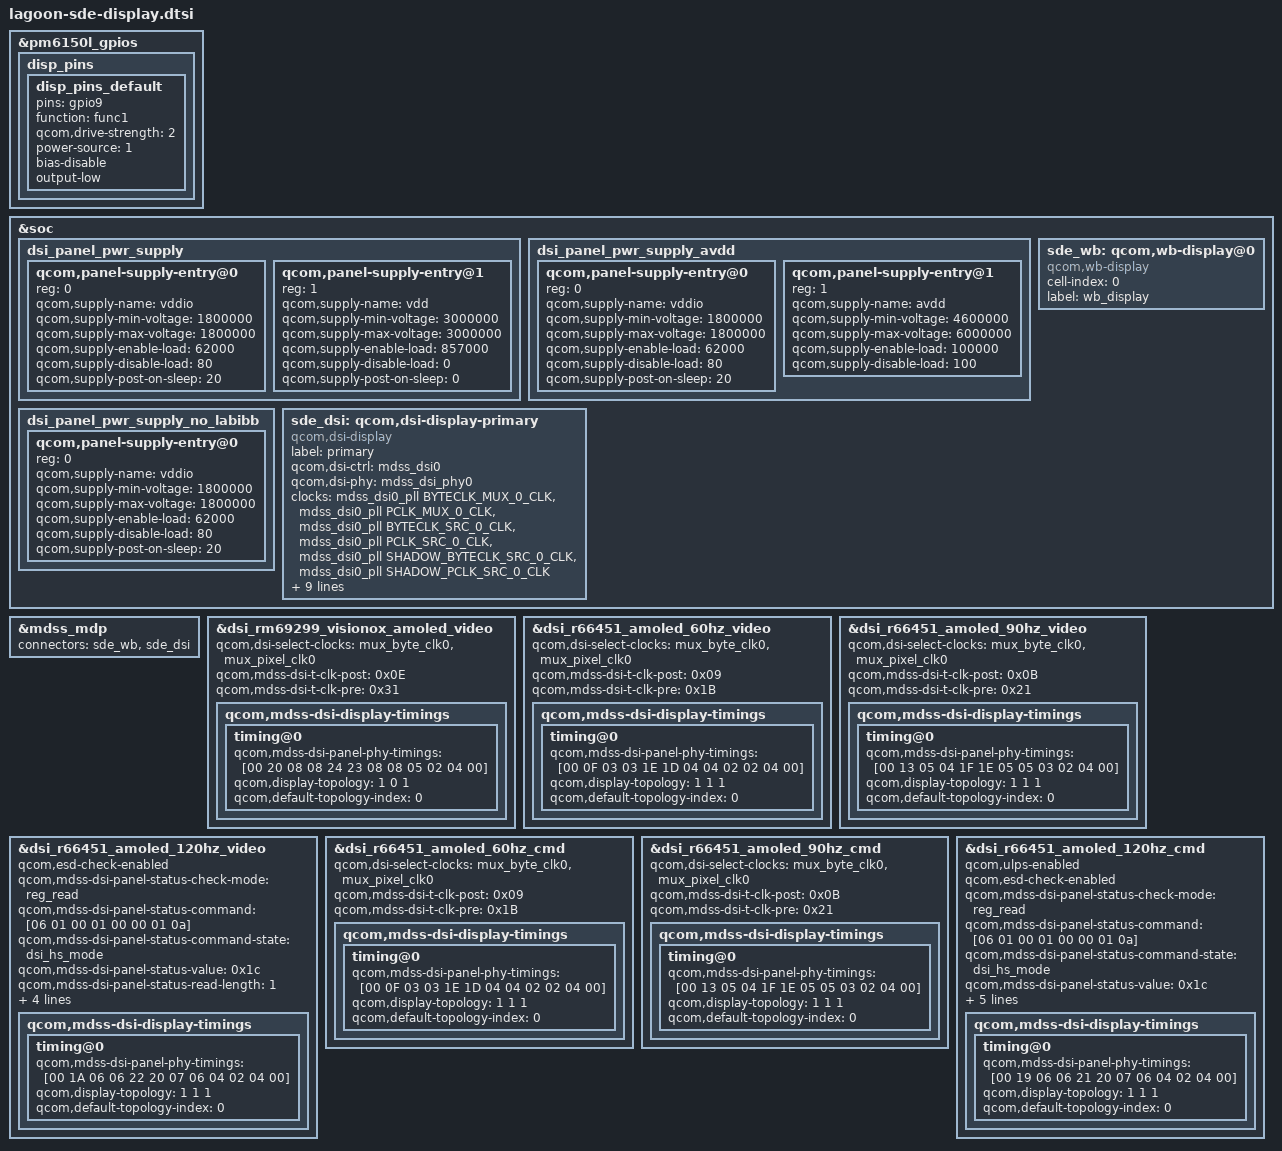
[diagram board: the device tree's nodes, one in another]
#include "dsi-panel-rm69299-visionox-fhd-plus-video.dtsi"
#include "dsi-panel-r66451-dsc-qhd-60hz-cmd.dtsi"
#include "dsi-panel-r66451-dsc-qhd-90hz-cmd.dtsi"
#include "dsi-panel-r66451-dsc-qhd-120hz-cmd.dtsi"
#include "dsi-panel-r66451-dsc-qhd-60hz-video.dtsi"
#include "dsi-panel-r66451-dsc-qhd-90hz-video.dtsi"
#include "dsi-panel-r66451-dsc-qhd-120hz-video.dtsi"

#include <dt-bindings/clock/mdss-10nm-pll-clk.h>

&pm6150l_gpios {
	disp_pins {
		disp_pins_default: disp_pins_default {
			pins = "gpio9";
			function = "func1";
			qcom,drive-strength = <2>;
			power-source = <1>;
			bias-disable;
			output-low;
		};
	};
};

&soc {
	dsi_panel_pwr_supply: dsi_panel_pwr_supply {
		#address-cells = <1>;
		#size-cells = <0>;

		qcom,panel-supply-entry@0 {
			reg = <0>;
			qcom,supply-name = "vddio";
			qcom,supply-min-voltage = <1800000>;
			qcom,supply-max-voltage = <1800000>;
			qcom,supply-enable-load = <62000>;
			qcom,supply-disable-load = <80>;
			qcom,supply-post-on-sleep = <20>;
		};

		qcom,panel-supply-entry@1 {
			reg = <1>;
			qcom,supply-name = "vdd";
			qcom,supply-min-voltage = <3000000>;
			qcom,supply-max-voltage = <3000000>;
			qcom,supply-enable-load = <857000>;
			qcom,supply-disable-load = <0>;
			qcom,supply-post-on-sleep = <0>;
		};
	};

	dsi_panel_pwr_supply_avdd: dsi_panel_pwr_supply_avdd {
		#address-cells = <1>;
		#size-cells = <0>;

		qcom,panel-supply-entry@0 {
			reg = <0>;
			qcom,supply-name = "vddio";
			qcom,supply-min-voltage = <1800000>;
			qcom,supply-max-voltage = <1800000>;
			qcom,supply-enable-load = <62000>;
			qcom,supply-disable-load = <80>;
			qcom,supply-post-on-sleep = <20>;
		};

		qcom,panel-supply-entry@1 {
			reg = <1>;
			qcom,supply-name = "avdd";
			qcom,supply-min-voltage = <4600000>;
			qcom,supply-max-voltage = <6000000>;
			qcom,supply-enable-load = <100000>;
			qcom,supply-disable-load = <100>;
		};
	};

	dsi_panel_pwr_supply_no_labibb: dsi_panel_pwr_supply_no_labibb {
		#address-cells = <1>;
		#size-cells = <0>;

		qcom,panel-supply-entry@0 {
			reg = <0>;
			qcom,supply-name = "vddio";
			qcom,supply-min-voltage = <1800000>;
			qcom,supply-max-voltage = <1800000>;
			qcom,supply-enable-load = <62000>;
			qcom,supply-disable-load = <80>;
			qcom,supply-post-on-sleep = <20>;
		};
	};

	sde_dsi: qcom,dsi-display-primary {
		compatible = "qcom,dsi-display";
		label = "primary";

		qcom,dsi-ctrl = <&mdss_dsi0>;
		qcom,dsi-phy = <&mdss_dsi_phy0>;

		clocks = <&mdss_dsi0_pll BYTECLK_MUX_0_CLK>,
			 <&mdss_dsi0_pll PCLK_MUX_0_CLK>,
			 <&mdss_dsi0_pll BYTECLK_SRC_0_CLK>,
			 <&mdss_dsi0_pll PCLK_SRC_0_CLK>,
			 <&mdss_dsi0_pll SHADOW_BYTECLK_SRC_0_CLK>,
			 <&mdss_dsi0_pll SHADOW_PCLK_SRC_0_CLK>;
		clock-names = "mux_byte_clk0", "mux_pixel_clk0",
				"src_byte_clk0", "src_pixel_clk0",
				"shadow_byte_clk0", "shadow_pixel_clk0";

		pinctrl-names = "panel_active", "panel_suspend";
		pinctrl-0 = <&sde_te_active &disp_pins_default>;
		pinctrl-1 = <&sde_te_suspend>;

		qcom,platform-te-gpio = <&tlmm 23 0>;
		qcom,panel-te-source = <0>;

		vddio-supply = <&L1E>;
		vdd-supply = <&L8A>;

		qcom,mdp = <&mdss_mdp>;
		qcom,dsi-default-panel = <&dsi_rm69299_visionox_amoled_video>;
	};

	sde_wb: qcom,wb-display@0 {
		compatible = "qcom,wb-display";
		cell-index = <0>;
		label = "wb_display";
	};
};

&mdss_mdp {
	connectors = <&sde_wb &sde_dsi>;
};

&dsi_rm69299_visionox_amoled_video {
	qcom,dsi-select-clocks = "mux_byte_clk0", "mux_pixel_clk0";
	qcom,mdss-dsi-t-clk-post = <0x0E>;
	qcom,mdss-dsi-t-clk-pre = <0x31>;
	qcom,mdss-dsi-display-timings {
		timing@0 {
			qcom,mdss-dsi-panel-phy-timings = [00 20 08 08 24 23 08
							08 05 02 04 00];
			qcom,display-topology = <1 0 1>;
			qcom,default-topology-index = <0>;
		};
	};
};

&dsi_r66451_amoled_60hz_video {
	qcom,dsi-select-clocks = "mux_byte_clk0", "mux_pixel_clk0";
	qcom,mdss-dsi-t-clk-post = <0x09>;
	qcom,mdss-dsi-t-clk-pre = <0x1B>;
	qcom,mdss-dsi-display-timings {
		timing@0 {
			qcom,mdss-dsi-panel-phy-timings = [00 0F 03 03 1E 1D 04
				04 02 02 04 00];
			qcom,display-topology = <1 1 1>;
			qcom,default-topology-index = <0>;
		};
	};
};

&dsi_r66451_amoled_90hz_video {
	qcom,dsi-select-clocks = "mux_byte_clk0", "mux_pixel_clk0";
	qcom,mdss-dsi-t-clk-post = <0x0B>;
	qcom,mdss-dsi-t-clk-pre = <0x21>;
	qcom,mdss-dsi-display-timings {
		timing@0 {
			qcom,mdss-dsi-panel-phy-timings = [00 13 05 04 1F 1E 05
				05 03 02 04 00];
			qcom,display-topology = <1 1 1>;
			qcom,default-topology-index = <0>;
		};
	};
};

&dsi_r66451_amoled_120hz_video {
	qcom,esd-check-enabled;
	qcom,mdss-dsi-panel-status-check-mode = "reg_read";
	qcom,mdss-dsi-panel-status-command = [06 01 00 01 00 00 01 0a];
	qcom,mdss-dsi-panel-status-command-state = "dsi_hs_mode";
	qcom,mdss-dsi-panel-status-value = <0x1c>;
	qcom,mdss-dsi-panel-status-read-length = <1>;
	qcom,dsi-select-clocks = "mux_byte_clk0", "mux_pixel_clk0";
	qcom,mdss-dsi-t-clk-post = <0x0C>;
	qcom,mdss-dsi-t-clk-pre = <0x29>;
	qcom,mdss-dsi-display-timings {
		timing@0 {
			qcom,mdss-dsi-panel-phy-timings = [00 1A 06 06 22 20 07
				06 04 02 04 00];
			qcom,display-topology = <1 1 1>;
			qcom,default-topology-index = <0>;
		};
	};
};

&dsi_r66451_amoled_60hz_cmd {
	qcom,dsi-select-clocks = "mux_byte_clk0", "mux_pixel_clk0";
	qcom,mdss-dsi-t-clk-post = <0x09>;
	qcom,mdss-dsi-t-clk-pre = <0x1B>;
	qcom,mdss-dsi-display-timings {
		timing@0 {
			qcom,mdss-dsi-panel-phy-timings = [00 0F 03 03 1E 1D 04
				04 02 02 04 00];
			qcom,display-topology = <1 1 1>;
			qcom,default-topology-index = <0>;
		};
	};
};

&dsi_r66451_amoled_90hz_cmd {
	qcom,dsi-select-clocks = "mux_byte_clk0", "mux_pixel_clk0";
	qcom,mdss-dsi-t-clk-post = <0x0B>;
	qcom,mdss-dsi-t-clk-pre = <0x21>;
	qcom,mdss-dsi-display-timings {
		timing@0 {
			qcom,mdss-dsi-panel-phy-timings = [00 13 05 04 1F 1E 05
				05 03 02 04 00];
			qcom,display-topology = <1 1 1>;
			qcom,default-topology-index = <0>;
		};
	};
};

&dsi_r66451_amoled_120hz_cmd {
	qcom,ulps-enabled;
	qcom,esd-check-enabled;
	qcom,mdss-dsi-panel-status-check-mode = "reg_read";
	qcom,mdss-dsi-panel-status-command = [06 01 00 01 00 00 01 0a];
	qcom,mdss-dsi-panel-status-command-state = "dsi_hs_mode";
	qcom,mdss-dsi-panel-status-value = <0x1c>;
	qcom,mdss-dsi-panel-status-read-length = <1>;
	qcom,dsi-select-clocks = "mux_byte_clk0", "mux_pixel_clk0";
	qcom,mdss-dsi-t-clk-post = <0x0C>;
	qcom,mdss-dsi-t-clk-pre = <0x28>;
	qcom,mdss-dsi-display-timings {
		timing@0 {
			qcom,mdss-dsi-panel-phy-timings = [00 19 06 06 21 20 07
				06 04 02 04 00];
			qcom,display-topology = <1 1 1>;
			qcom,default-topology-index = <0>;
		};
	};
};
